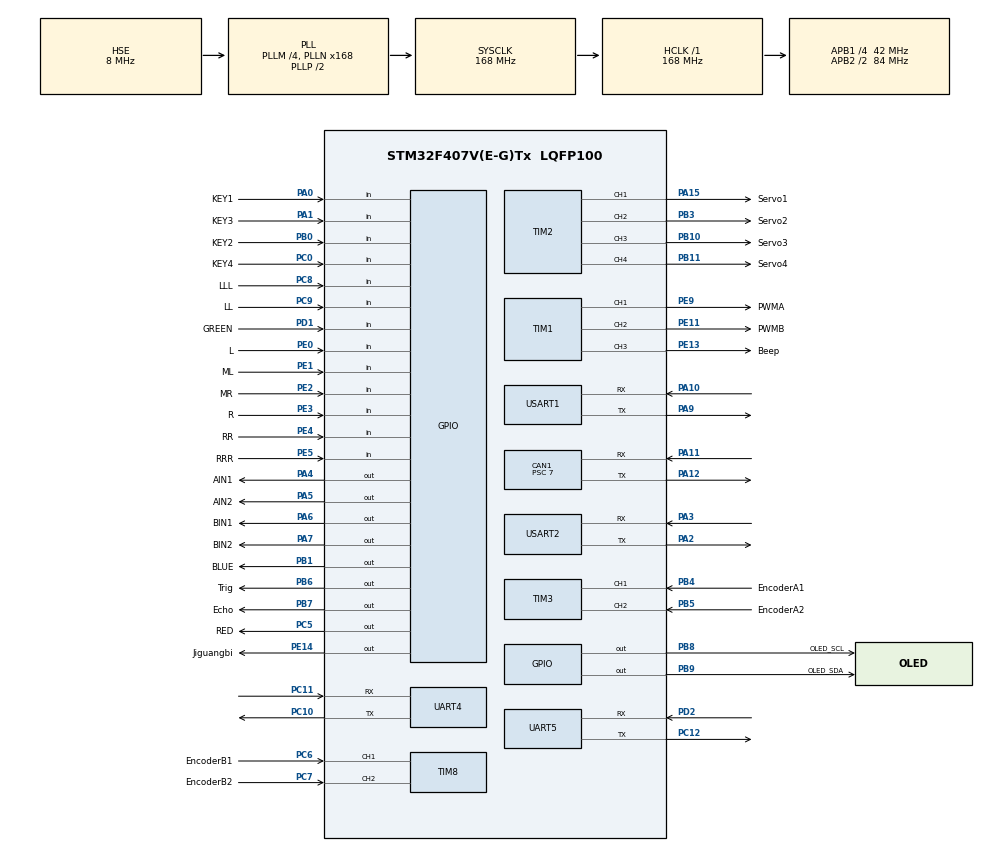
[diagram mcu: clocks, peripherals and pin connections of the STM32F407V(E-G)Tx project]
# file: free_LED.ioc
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CAN1.BS1=CAN_BS1_3TQ
CAN1.BS2=CAN_BS2_2TQ
CAN1.CalculateBaudRate=999999
CAN1.CalculateTimeBit=1000
CAN1.CalculateTimeQuantum=166.66666666666669
CAN1.Mode=CAN_MODE_SILENT_LOOPBACK
CAN1.Prescaler=7
Mcu.Family=STM32F4
Mcu.Name=STM32F407V(E-G)Tx
Mcu.Package=LQFP100
NVIC.CAN1_RX0_IRQn=true\:0\:0\:false\:false\:true\:true\:true\:true
NVIC.CAN1_RX1_IRQn=true\:0\:0\:false\:false\:true\:true\:true\:true
NVIC.PriorityGroup=NVIC_PRIORITYGROUP_4
NVIC.USART1_IRQn=true\:0\:0\:false\:false\:true\:true\:true\:true
PA0-WKUP.GPIO_Label=KEY1
PA0-WKUP.Signal=GPIO_Input
PA1.GPIO_Label=KEY3
PA1.Signal=GPIO_Input
PA10.Mode=Asynchronous
PA10.Signal=USART1_RX
PA11.Mode=CAN_Activate
PA11.Signal=CAN1_RX
PA12.Mode=CAN_Activate
PA12.Signal=CAN1_TX
PA13.Mode=Serial_Wire
PA13.Signal=SYS_JTMS-SWDIO
PA14.Mode=Serial_Wire
PA14.Signal=SYS_JTCK-SWCLK
PA15.GPIO_Label=Servo1
PA15.Signal=S_TIM2_CH1_ETR
PA2.Mode=Asynchronous
PA2.Signal=USART2_TX
PA3.Mode=Asynchronous
PA3.Signal=USART2_RX
PA4.GPIO_Label=AIN1
PA4.Signal=GPIO_Output
PA5.GPIO_Label=AIN2
PA5.Signal=GPIO_Output
PA6.GPIO_Label=BIN1
PA6.Signal=GPIO_Output
PA7.GPIO_Label=BIN2
PA7.Signal=GPIO_Output
PA9.Mode=Asynchronous
PA9.Signal=USART1_TX
PB0.GPIO_Label=KEY2
PB0.Signal=GPIO_Input
PB1.GPIO_Label=BLUE
PB1.Signal=GPIO_Output
PB10.GPIO_Label=Servo3
PB10.Signal=S_TIM2_CH3
PB11.GPIO_Label=Servo4
PB11.Signal=S_TIM2_CH4
PB3.GPIO_Label=Servo2
PB3.Signal=S_TIM2_CH2
PB4.GPIO_Label=EncoderA1
PB4.Signal=S_TIM3_CH1
PB5.GPIO_Label=EncoderA2
PB5.Signal=S_TIM3_CH2
PB6.GPIO_Label=Trig
PB6.Signal=GPIO_Output
PB7.GPIO_Label=Echo
PB7.Signal=GPIO_Output
PB8.GPIO_Label=OLED_SCL
PB8.GPIO_ModeDefaultOutputPP=GPIO_MODE_OUTPUT_OD
PB8.GPIO_PuPd=GPIO_NOPULL
PB8.Signal=GPIO_Output
PB9.GPIO_Label=OLED_SDA
PB9.GPIO_ModeDefaultOutputPP=GPIO_MODE_OUTPUT_OD
PB9.GPIO_PuPd=GPIO_NOPULL
PB9.Signal=GPIO_Output
PC0.GPIO_Label=KEY4
PC0.Signal=GPIO_Input
PC10.Mode=Asynchronous
PC10.Signal=UART4_TX
PC11.Mode=Asynchronous
PC11.Signal=UART4_RX
PC12.Mode=Asynchronous
PC12.Signal=UART5_TX
PC5.GPIO_Label=RED
PC5.Signal=GPIO_Output
PC6.GPIO_Label=EncoderB1
PC6.Signal=S_TIM8_CH1
PC7.GPIO_Label=EncoderB2
PC7.Signal=S_TIM8_CH2
PC8.GPIO_Label=LLL
PC8.Signal=GPIO_Input
PC9.GPIO_Label=LL
PC9.Signal=GPIO_Input
PD1.GPIO_Label=GREEN
PD1.Signal=GPIO_Input
PD2.Mode=Asynchronous
PD2.Signal=UART5_RX
PE0.GPIO_Label=L
PE0.Signal=GPIO_Input
PE1.GPIO_Label=ML
PE1.Signal=GPIO_Input
PE11.GPIO_Label=PWMB
PE11.Signal=S_TIM1_CH2
PE13.GPIO_Label=Beep
PE13.Signal=S_TIM1_CH3
PE14.GPIO_Label=Jiguangbi
PE14.Signal=GPIO_Output
PE2.GPIO_Label=MR
PE2.Signal=GPIO_Input
PE3.GPIO_Label=R
PE3.Signal=GPIO_Input
PE4.GPIO_Label=RR
PE4.Signal=GPIO_Input
PE5.GPIO_Label=RRR
PE5.Signal=GPIO_Input
PE9.GPIO_Label=PWMA
PE9.Signal=S_TIM1_CH1
PH0-OSC_IN.Mode=HSE-External-Oscillator
PH0-OSC_IN.Signal=RCC_OSC_IN
PH1-OSC_OUT.Mode=HSE-External-Oscillator
PH1-OSC_OUT.Signal=RCC_OSC_OUT
ProjectManager.HeapSize=0x200
ProjectManager.StackSize=0x400
ProjectManager.TargetToolchain=CMake
RCC.48MHZClocksFreq_Value=84000000
RCC.AHBFreq_Value=168000000
RCC.APB1CLKDivider=RCC_HCLK_DIV4
RCC.APB1Freq_Value=42000000
RCC.APB1TimFreq_Value=84000000
RCC.APB2CLKDivider=RCC_HCLK_DIV2
RCC.APB2Freq_Value=84000000
RCC.APB2TimFreq_Value=168000000
RCC.CortexFreq_Value=168000000
RCC.HCLKFreq_Value=168000000
RCC.HSE_VALUE=8000000
RCC.HSI_VALUE=16000000
RCC.LSE_VALUE=32768
RCC.PLLM=4
RCC.PLLN=168
RCC.PLLSourceVirtual=RCC_PLLSOURCE_HSE
RCC.SYSCLKFreq_VALUE=168000000
RCC.SYSCLKSource=RCC_SYSCLKSOURCE_PLLCLK
RCC.VCOOutputFreq_Value=336000000
SH.S_TIM1_CH1.0=TIM1_CH1,PWM Generation1 CH1
SH.S_TIM1_CH2.0=TIM1_CH2,PWM Generation2 CH2
SH.S_TIM1_CH3.0=TIM1_CH3,PWM Generation3 CH3
SH.S_TIM2_CH1_ETR.0=TIM2_CH1,PWM Generation1 CH1
SH.S_TIM2_CH2.0=TIM2_CH2,PWM Generation2 CH2
SH.S_TIM2_CH3.0=TIM2_CH3,PWM Generation3 CH3
SH.S_TIM2_CH4.0=TIM2_CH4,PWM Generation4 CH4
SH.S_TIM3_CH1.0=TIM3_CH1,Encoder_Interface
SH.S_TIM3_CH2.0=TIM3_CH2,Encoder_Interface
SH.S_TIM8_CH1.0=TIM8_CH1,Encoder_Interface
SH.S_TIM8_CH2.0=TIM8_CH2,Encoder_Interface
TIM1.Channel-PWM\ Generation1\ CH1=TIM_CHANNEL_1
TIM1.Channel-PWM\ Generation2\ CH2=TIM_CHANNEL_2
TIM1.Channel-PWM\ Generation3\ CH3=TIM_CHANNEL_3
TIM2.Channel-PWM\ Generation1\ CH1=TIM_CHANNEL_1
TIM2.Channel-PWM\ Generation2\ CH2=TIM_CHANNEL_2
TIM2.Channel-PWM\ Generation3\ CH3=TIM_CHANNEL_3
TIM2.Channel-PWM\ Generation4\ CH4=TIM_CHANNEL_4
UART4.VirtualMode=Asynchronous
UART5.VirtualMode=Asynchronous
USART1.VirtualMode=VM_ASYNC
USART2.VirtualMode=VM_ASYNC
board=custom

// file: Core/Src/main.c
/* USER CODE BEGIN Header */
/**
  ******************************************************************************
  * @file           : main.c
  * @brief          : Main program body
  ******************************************************************************
  * @attention
  *
  * Copyright (c) 2026 STMicroelectronics.
  * All rights reserved.
  *
  * This software is licensed under terms that can be found in the LICENSE file
  * in the root directory of this software component.
  * If no LICENSE file comes with this software, it is provided AS-IS.
  *
  ******************************************************************************
  */
/* USER CODE END Header */
#include "main.h"
#include "bsp_led.h"
#include "can.h"
#include "stm32f4xx_hal_uart.h"
#include "tim.h"
#include "usart.h"
#include "gpio.h"
#include "oled.h"
/* USER CODE BEGIN Includes */
#include "bsp.h"
#include "bsp_usart.h"
#include <stdint.h>
/* USER CODE END Includes */

void SystemClock_Config(void);

int main(void)
{

  /* MCU Configuration--------------------------------------------------------*/

  /* Reset of all peripherals, Initializes the Flash interface and the Systick. */
  HAL_Init();

  /* Configure the system clock */
  SystemClock_Config();

  /* Initialize all configured peripherals */
  MX_GPIO_Init();
  MX_CAN1_Init();
  MX_TIM1_Init();
  MX_TIM2_Init();
  MX_TIM3_Init();
  MX_TIM8_Init();
  MX_UART4_Init();
  MX_UART5_Init();
  MX_USART1_UART_Init();
  MX_USART2_UART_Init();
  /* USER CODE BEGIN 2 */
  USART1_Init();
  OLED_Init();
  OLED_ShowString(1, 1, "Hello, World!");
  /* USER CODE END 2 */

  /* Infinite loop */
  /* USER CODE BEGIN WHILE */
  uint8_t hello_msg[] = "Hello";
  while (1)
  {
    USART1_Send_IT(hello_msg, 5);
    HAL_Delay(1000);
    /* USER CODE END WHILE */

  }
}

void SystemClock_Config(void)
{
  RCC_OscInitTypeDef RCC_OscInitStruct = {0};
  RCC_ClkInitTypeDef RCC_ClkInitStruct = {0};

  /** Configure the main internal regulator output voltage
  */
  __HAL_RCC_PWR_CLK_ENABLE();
  __HAL_PWR_VOLTAGESCALING_CONFIG(PWR_REGULATOR_VOLTAGE_SCALE1);

  /** Initializes the RCC Oscillators according to the specified parameters
  * in the RCC_OscInitTypeDef structure.
  */
  RCC_OscInitStruct.OscillatorType = RCC_OSCILLATORTYPE_HSE;
  RCC_OscInitStruct.HSEState = RCC_HSE_ON;
  RCC_OscInitStruct.PLL.PLLState = RCC_PLL_ON;
  RCC_OscInitStruct.PLL.PLLSource = RCC_PLLSOURCE_HSE;
  RCC_OscInitStruct.PLL.PLLM = 4;
  RCC_OscInitStruct.PLL.PLLN = 168;
  RCC_OscInitStruct.PLL.PLLP = RCC_PLLP_DIV2;
  RCC_OscInitStruct.PLL.PLLQ = 4;
  if (HAL_RCC_OscConfig(&RCC_OscInitStruct) != HAL_OK)
  {
    Error_Handler();
  }

  /** Initializes the CPU, AHB and APB buses clocks
  */
  RCC_ClkInitStruct.ClockType = RCC_CLOCKTYPE_HCLK|RCC_CLOCKTYPE_SYSCLK
                              |RCC_CLOCKTYPE_PCLK1|RCC_CLOCKTYPE_PCLK2;
  RCC_ClkInitStruct.SYSCLKSource = RCC_SYSCLKSOURCE_PLLCLK;
  RCC_ClkInitStruct.AHBCLKDivider = RCC_SYSCLK_DIV1;
  RCC_ClkInitStruct.APB1CLKDivider = RCC_HCLK_DIV4;
  RCC_ClkInitStruct.APB2CLKDivider = RCC_HCLK_DIV2;

  if (HAL_RCC_ClockConfig(&RCC_ClkInitStruct, FLASH_LATENCY_5) != HAL_OK)
  {
    Error_Handler();
  }
}

void Error_Handler(void)
{
  __disable_irq();
  while (1)
  {
  }
}
